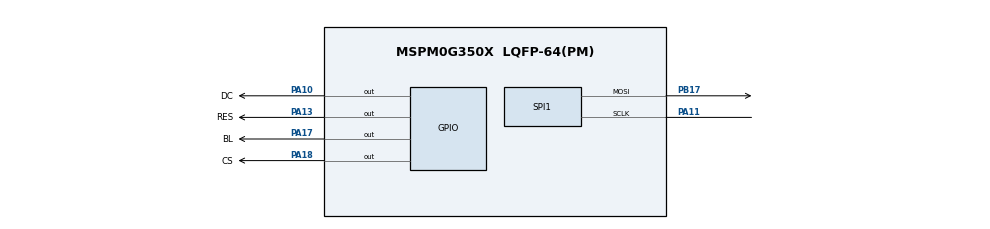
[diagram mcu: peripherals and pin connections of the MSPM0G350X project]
/**
 * @cliArgs --device "MSPM0G350X" --part "Default" --package "LQFP-64(PM)" --product "mspm0_sdk@2.04.00.06"
 * @versions {"tool":"1.23.0+4000"}
 */

/**
 * Import the modules used in this configuration.
 */
const GPIO   = scripting.addModule("/ti/driverlib/GPIO", {}, false);
const GPIO1  = GPIO.addInstance();
const SPI    = scripting.addModule("/ti/driverlib/SPI", {}, false);
const SPI1   = SPI.addInstance();
const SYSCTL = scripting.addModule("/ti/driverlib/SYSCTL");

/**
 * Write custom configuration values to the imported modules.
 */
GPIO1.$name                                 = "TFT";
GPIO1.port                                  = "PORTA";
GPIO1.associatedPins.create(4);
GPIO1.associatedPins[0].$name               = "DC";
GPIO1.associatedPins[0].assignedPortSegment = "Lower";
GPIO1.associatedPins[0].assignedPin         = "10";
GPIO1.associatedPins[0].internalResistor    = "PULL_UP";
GPIO1.associatedPins[0].pin.$assign         = "PA10";
GPIO1.associatedPins[1].$name               = "RES";
GPIO1.associatedPins[1].assignedPortSegment = "Lower";
GPIO1.associatedPins[1].assignedPin         = "13";
GPIO1.associatedPins[1].internalResistor    = "PULL_UP";
GPIO1.associatedPins[1].pin.$assign         = "PA13";
GPIO1.associatedPins[2].$name               = "CS";
GPIO1.associatedPins[2].assignedPortSegment = "Upper";
GPIO1.associatedPins[2].assignedPin         = "18";
GPIO1.associatedPins[2].internalResistor    = "PULL_UP";
GPIO1.associatedPins[2].initialValue        = "SET";
GPIO1.associatedPins[2].pin.$assign         = "PA18";
GPIO1.associatedPins[3].$name               = "BL";
GPIO1.associatedPins[3].assignedPortSegment = "Upper";
GPIO1.associatedPins[3].assignedPin         = "17";
GPIO1.associatedPins[3].internalResistor    = "PULL_UP";
GPIO1.associatedPins[3].initialValue        = "SET";
GPIO1.associatedPins[3].pin.$assign         = "PA17";

const Board = scripting.addModule("/ti/driverlib/Board", {}, false);

SPI1.$name                              = "TFT_SPI";
SPI1.peripheral.sclkPin.$assign         = "PA11";
SPI1.peripheral.mosiPin.$assign         = "PB17";
SPI1.sclkPinConfig.$name                = "ti_driverlib_gpio_GPIOPinGeneric0";
SPI1.sclkPinConfig.direction            = scripting.forceWrite("OUTPUT");
SPI1.sclkPinConfig.onlyInternalResistor = scripting.forceWrite(false);
SPI1.sclkPinConfig.passedPeripheralType = scripting.forceWrite("Digital");
SPI1.mosiPinConfig.$name                = "ti_driverlib_gpio_GPIOPinGeneric1";
SPI1.mosiPinConfig.direction            = scripting.forceWrite("OUTPUT");
SPI1.mosiPinConfig.hideOutputInversion  = scripting.forceWrite(false);
SPI1.mosiPinConfig.onlyInternalResistor = scripting.forceWrite(false);
SPI1.mosiPinConfig.passedPeripheralType = scripting.forceWrite("Digital");
SPI1.misoPinConfig.$name                = "ti_driverlib_gpio_GPIOPinGeneric2";
SPI1.misoPinConfig.onlyInternalResistor = scripting.forceWrite(false);
SPI1.misoPinConfig.passedPeripheralType = scripting.forceWrite("Digital");
SPI1.cs0PinConfig.$name                 = "ti_driverlib_gpio_GPIOPinGeneric3";
SPI1.cs0PinConfig.direction             = scripting.forceWrite("OUTPUT");
SPI1.cs0PinConfig.hideOutputInversion   = scripting.forceWrite(false);
SPI1.cs0PinConfig.onlyInternalResistor  = scripting.forceWrite(false);
SPI1.cs0PinConfig.passedPeripheralType  = scripting.forceWrite("Digital");

SYSCTL.forceDefaultClkConfig = true;

/**
 * Pinmux solution for unlocked pins/peripherals. This ensures that minor changes to the automatic solver in a future
 * version of the tool will not impact the pinmux you originally saw.  These lines can be completely deleted in order to
 * re-solve from scratch.
 */
Board.peripheral.$suggestSolution          = "DEBUGSS";
Board.peripheral.swclkPin.$suggestSolution = "PA20";
Board.peripheral.swdioPin.$suggestSolution = "PA19";
SPI1.peripheral.$suggestSolution           = "SPI0";
SPI1.peripheral.misoPin.$suggestSolution   = "PA4";
SPI1.peripheral.cs0Pin.$suggestSolution    = "PA2";
SYSCTL.peripheral.$suggestSolution         = "SYSCTL";
